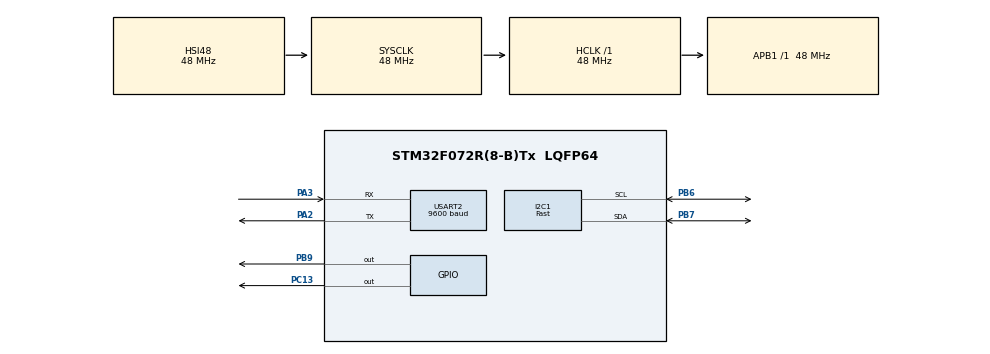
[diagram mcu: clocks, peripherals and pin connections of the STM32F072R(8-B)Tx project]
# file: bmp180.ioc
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I2C1.I2C_Speed_Mode=I2C_Fast
I2C1.Timing=0x0000020B
Mcu.Family=STM32F0
Mcu.Name=STM32F072R(8-B)Tx
Mcu.Package=LQFP64
NVIC.USART2_IRQn=true\:0\:0\:false\:false\:true\:true\:true
PA13.Mode=Serial_Wire
PA13.Signal=SYS_SWDIO
PA14.Mode=Serial_Wire
PA14.Signal=SYS_SWCLK
PA2.Mode=Asynchronous
PA2.Signal=USART2_TX
PA3.Mode=Asynchronous
PA3.Signal=USART2_RX
PB6.Mode=I2C
PB6.Signal=I2C1_SCL
PB7.Mode=I2C
PB7.Signal=I2C1_SDA
PB9.Signal=GPIO_Output
PC13.Signal=GPIO_Output
PF0-OSC_IN.Mode=HSE-External-Oscillator
PF0-OSC_IN.Signal=RCC_OSC_IN
PF1-OSC_OUT.Mode=HSE-External-Oscillator
PF1-OSC_OUT.Signal=RCC_OSC_OUT
ProjectManager.HeapSize=0x200
ProjectManager.StackSize=0x400
ProjectManager.TargetToolchain=MDK-ARM V5.27
RCC.AHBFreq_Value=48000000
RCC.APB1Freq_Value=48000000
RCC.APB1TimFreq_Value=48000000
RCC.FLatency-AdvancedSettings=FLASH_LATENCY_1
RCC.HCLKFreq_Value=48000000
RCC.PLLDivider=RCC_PREDIV_DIV2
RCC.PLLMUL=RCC_PLL_MUL12
RCC.PREFETCH_ENABLE-AdvancedSettings=1
RCC.SYSCLKFreq_VALUE=48000000
RCC.SYSCLKSource=RCC_SYSCLKSOURCE_HSI48
USART2.BaudRate=9600
USART2.VirtualMode-Asynchronous=VM_ASYNC
board=NUCLEO-F072RB

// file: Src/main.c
/* USER CODE BEGIN Header */
/**
  ******************************************************************************
  * @file           : main.c
  * @brief          : Main program body
  ******************************************************************************
  * @attention
  *
  * <h2><center>&copy; Copyright (c) 2020 STMicroelectronics.
  * All rights reserved.</center></h2>
  *
  * This software component is licensed by ST under BSD 3-Clause license,
  * the "License"; You may not use this file except in compliance with the
  * License. You may obtain a copy of the License at:
  *                        opensource.org/licenses/BSD-3-Clause
  *
  ******************************************************************************
  */
/* USER CODE END Header */
#include "main.h"
#include "stdio.h"
#include "BMP180.h"

I2C_HandleTypeDef hi2c1;

UART_HandleTypeDef huart2;

/* USER CODE BEGIN PV */
char buffer[176];
static char* uartTX= "MERHABA UART BEGAN \t\n";
/* USER CODE END PV */

void SystemClock_Config(void);
static void MX_GPIO_Init(void);
static void MX_I2C1_Init(void);
static void MX_USART2_UART_Init(void);

/* USER CODE BEGIN 0 */
float Temparature;
float Pressure;
float Altitude;
/* USER CODE END 0 */

int main(void)
{

  /* MCU Configuration--------------------------------------------------------*/

  /* Reset of all peripherals, Initializes the Flash interface and the Systick. */
  HAL_Init();

  /* Configure the system clock */
  SystemClock_Config();

  /* Initialize all configured peripherals */
  MX_GPIO_Init();
  MX_I2C1_Init();
  MX_USART2_UART_Init();
  /* USER CODE BEGIN 2 */
if(HAL_UART_Transmit(&huart2, (uint8_t *)uartTX,25,1000)!=HAL_OK)
   {
      Error_Handler();

	 }
  /* USER CODE END 2 */
  BMP180_Start();
  /* Infinite loop */
  while (1)
  {
     Temparature = BMP180_GetTemp();
		 Pressure = BMP180_GetPress(0);
		 Altitude = BMP180_GetAlt(0);

		 HAL_Delay(2000);
		sprintf(buffer,"Temparature: %f Pressure: %f Altitude: %f \r\n", Temparature,Pressure,Altitude);
		while(HAL_UART_GetState(&huart2)!= HAL_UART_STATE_READY);
		if( HAL_UART_Transmit(&huart2,(uint8_t*)buffer,sizeof(buffer),100) != HAL_OK)
		{

			Error_Handler();
		}
    /* USER CODE BEGIN 3 */
  }

    /* USER CODE BEGIN 3 */
  }
  /* USER CODE END 3 */

void SystemClock_Config(void)
{
  RCC_OscInitTypeDef RCC_OscInitStruct = {0};
  RCC_ClkInitTypeDef RCC_ClkInitStruct = {0};
  RCC_PeriphCLKInitTypeDef PeriphClkInit = {0};

  /** Initializes the RCC Oscillators according to the specified parameters
  * in the RCC_OscInitTypeDef structure.
  */
  RCC_OscInitStruct.OscillatorType = RCC_OSCILLATORTYPE_HSI|RCC_OSCILLATORTYPE_HSI48;
  RCC_OscInitStruct.HSIState = RCC_HSI_ON;
  RCC_OscInitStruct.HSI48State = RCC_HSI48_ON;
  RCC_OscInitStruct.HSICalibrationValue = RCC_HSICALIBRATION_DEFAULT;
  RCC_OscInitStruct.PLL.PLLState = RCC_PLL_NONE;
  if (HAL_RCC_OscConfig(&RCC_OscInitStruct) != HAL_OK)
  {
    Error_Handler();
  }
  /** Initializes the CPU, AHB and APB buses clocks
  */
  RCC_ClkInitStruct.ClockType = RCC_CLOCKTYPE_HCLK|RCC_CLOCKTYPE_SYSCLK
                              |RCC_CLOCKTYPE_PCLK1;
  RCC_ClkInitStruct.SYSCLKSource = RCC_SYSCLKSOURCE_HSI48;
  RCC_ClkInitStruct.AHBCLKDivider = RCC_SYSCLK_DIV1;
  RCC_ClkInitStruct.APB1CLKDivider = RCC_HCLK_DIV1;

  if (HAL_RCC_ClockConfig(&RCC_ClkInitStruct, FLASH_LATENCY_1) != HAL_OK)
  {
    Error_Handler();
  }
  PeriphClkInit.PeriphClockSelection = RCC_PERIPHCLK_USART2|RCC_PERIPHCLK_I2C1;
  PeriphClkInit.Usart2ClockSelection = RCC_USART2CLKSOURCE_PCLK1;
  PeriphClkInit.I2c1ClockSelection = RCC_I2C1CLKSOURCE_HSI;
  if (HAL_RCCEx_PeriphCLKConfig(&PeriphClkInit) != HAL_OK)
  {
    Error_Handler();
  }
}

static void MX_I2C1_Init(void)
{

  hi2c1.Instance = I2C1;
  hi2c1.Init.Timing = 0x0000020B;
  hi2c1.Init.OwnAddress1 = 0;
  hi2c1.Init.AddressingMode = I2C_ADDRESSINGMODE_7BIT;
  hi2c1.Init.DualAddressMode = I2C_DUALADDRESS_DISABLE;
  hi2c1.Init.OwnAddress2 = 0;
  hi2c1.Init.OwnAddress2Masks = I2C_OA2_NOMASK;
  hi2c1.Init.GeneralCallMode = I2C_GENERALCALL_DISABLE;
  hi2c1.Init.NoStretchMode = I2C_NOSTRETCH_DISABLE;
  if (HAL_I2C_Init(&hi2c1) != HAL_OK)
  {
    Error_Handler();
  }
  /** Configure Analogue filter
  */
  if (HAL_I2CEx_ConfigAnalogFilter(&hi2c1, I2C_ANALOGFILTER_ENABLE) != HAL_OK)
  {
    Error_Handler();
  }
  /** Configure Digital filter
  */
  if (HAL_I2CEx_ConfigDigitalFilter(&hi2c1, 0) != HAL_OK)
  {
    Error_Handler();
  }

}

static void MX_USART2_UART_Init(void)
{

  huart2.Instance = USART2;
  huart2.Init.BaudRate = 9600;
  huart2.Init.WordLength = UART_WORDLENGTH_8B;
  huart2.Init.StopBits = UART_STOPBITS_1;
  huart2.Init.Parity = UART_PARITY_NONE;
  huart2.Init.Mode = UART_MODE_TX_RX;
  huart2.Init.HwFlowCtl = UART_HWCONTROL_NONE;
  huart2.Init.OverSampling = UART_OVERSAMPLING_16;
  huart2.Init.OneBitSampling = UART_ONE_BIT_SAMPLE_DISABLE;
  huart2.AdvancedInit.AdvFeatureInit = UART_ADVFEATURE_NO_INIT;
  if (HAL_UART_Init(&huart2) != HAL_OK)
  {
    Error_Handler();
  }

}

static void MX_GPIO_Init(void)
{
  GPIO_InitTypeDef GPIO_InitStruct = {0};

  /* GPIO Ports Clock Enable */
  __HAL_RCC_GPIOC_CLK_ENABLE();
  __HAL_RCC_GPIOF_CLK_ENABLE();
  __HAL_RCC_GPIOA_CLK_ENABLE();
  __HAL_RCC_GPIOB_CLK_ENABLE();

  /*Configure GPIO pin Output Level */
  HAL_GPIO_WritePin(GPIOC, GPIO_PIN_13, GPIO_PIN_RESET);

  /*Configure GPIO pin Output Level */
  HAL_GPIO_WritePin(GPIOB, GPIO_PIN_9, GPIO_PIN_RESET);

  /*Configure GPIO pin : PC13 */
  GPIO_InitStruct.Pin = GPIO_PIN_13;
  GPIO_InitStruct.Mode = GPIO_MODE_OUTPUT_PP;
  GPIO_InitStruct.Pull = GPIO_NOPULL;
  GPIO_InitStruct.Speed = GPIO_SPEED_FREQ_LOW;
  HAL_GPIO_Init(GPIOC, &GPIO_InitStruct);

  /*Configure GPIO pin : PB9 */
  GPIO_InitStruct.Pin = GPIO_PIN_9;
  GPIO_InitStruct.Mode = GPIO_MODE_OUTPUT_PP;
  GPIO_InitStruct.Pull = GPIO_NOPULL;
  GPIO_InitStruct.Speed = GPIO_SPEED_FREQ_LOW;
  HAL_GPIO_Init(GPIOB, &GPIO_InitStruct);

}

void Error_Handler(void)
{
}

/************************ (C) COPYRIGHT STMicroelectronics *****END OF FILE****/
